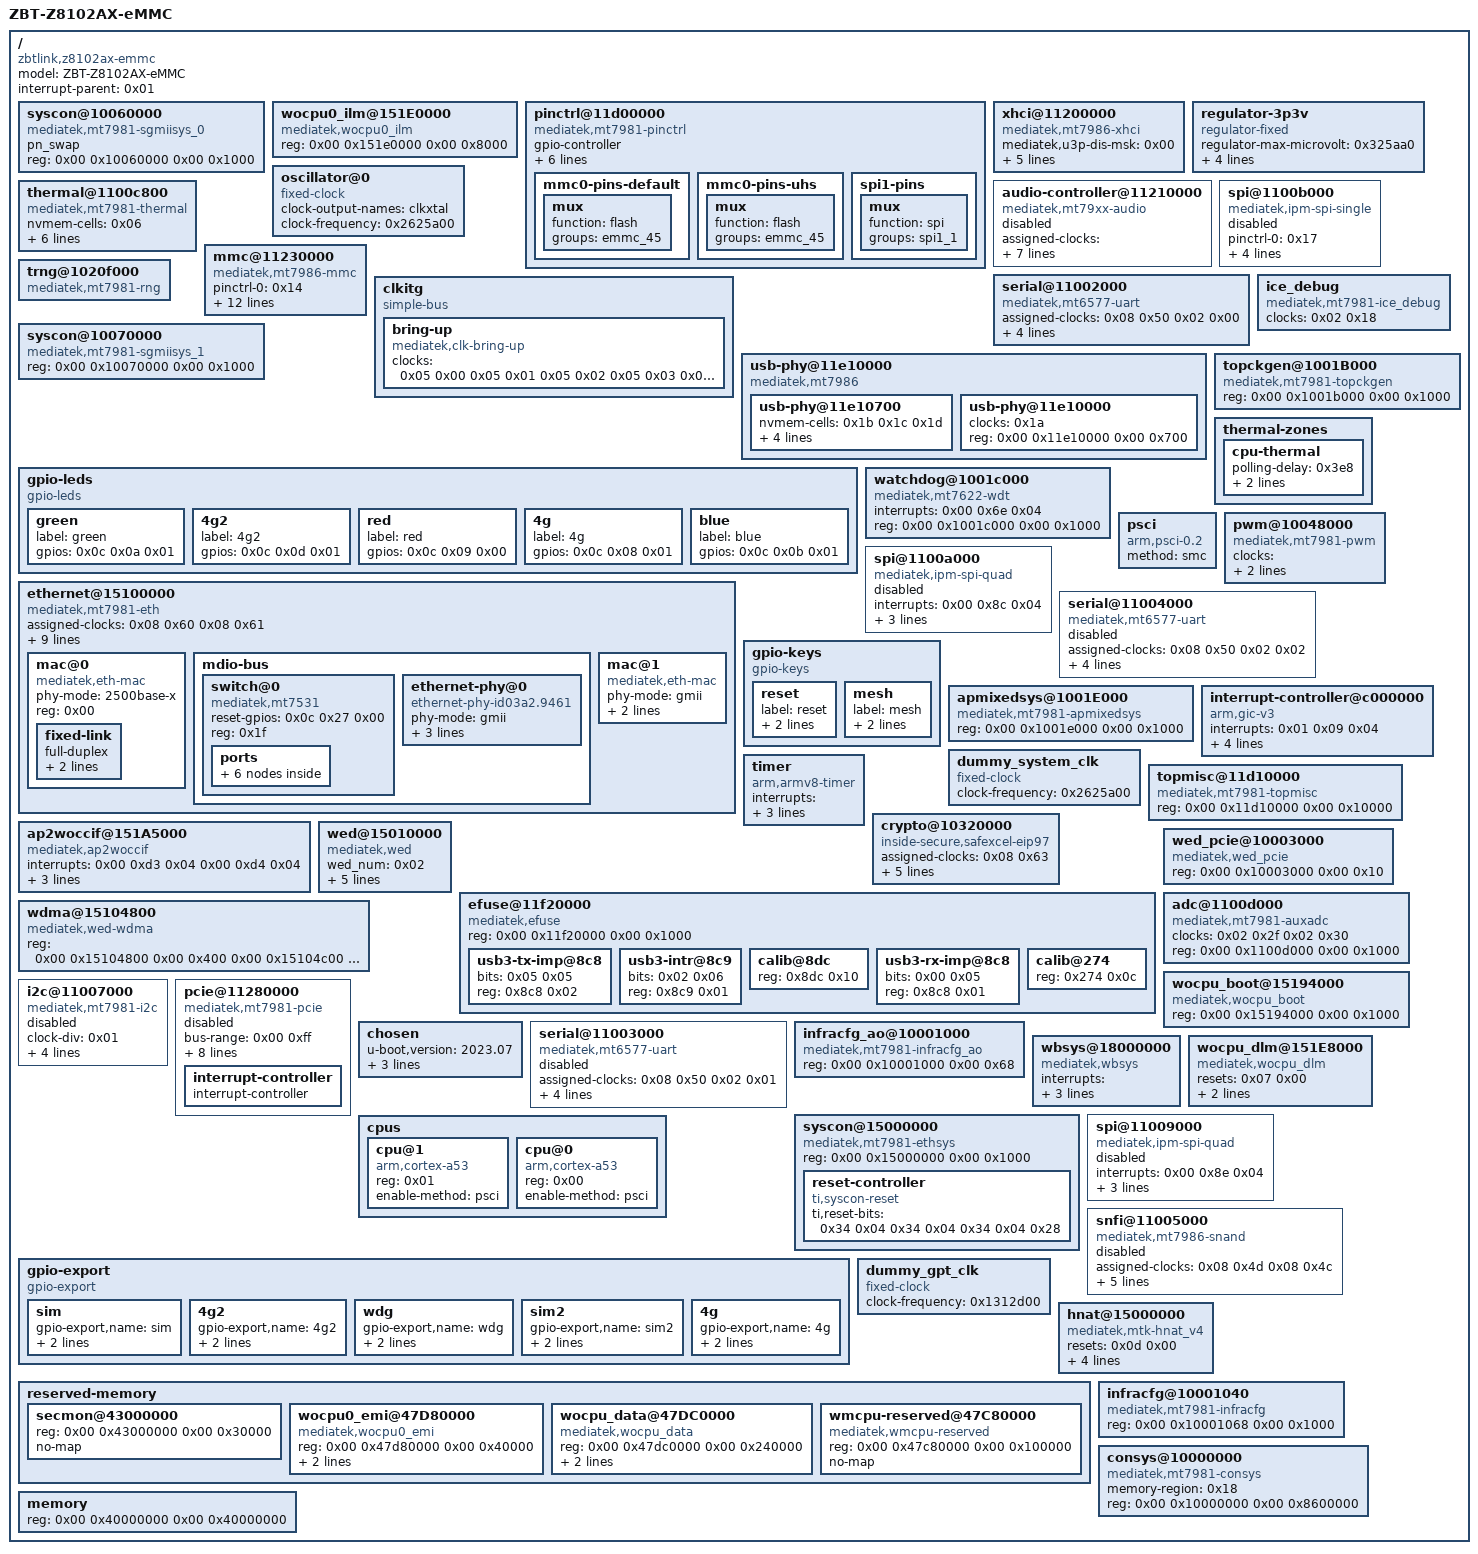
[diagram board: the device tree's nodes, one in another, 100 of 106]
/dts-v1/;

/ {
	#address-cells = <0x02>;
	model = "ZBT-Z8102AX-eMMC";
	#size-cells = <0x02>;
	interrupt-parent = <0x01>;
	compatible = "zbtlink,z8102ax-emmc\0mediatek,mt7981-emmc-rfb";

	syscon@10060000 {
		pn_swap;
		#clock-cells = <0x01>;
		compatible = "mediatek,mt7981-sgmiisys_0\0syscon";
		reg = <0x00 0x10060000 0x00 0x1000>;
		phandle = <0x0e>;
	};

	wocpu0_ilm@151E0000 {
		compatible = "mediatek,wocpu0_ilm";
		reg = <0x00 0x151e0000 0x00 0x8000>;
	};

	pinctrl@11d00000 {
		reg-names = "gpio_base\0iocfg_rt_base\0iocfg_rm_base\0iocfg_rb_base\0iocfg_lb_base\0iocfg_bl_base\0iocfg_tm_base\0iocfg_tl_base\0eint";
		gpio-controller;
		interrupts = <0x00 0xe1 0x04>;
		interrupt-parent = <0x01>;
		compatible = "mediatek,mt7981-pinctrl";
		#interrupt-cells = <0x02>;
		reg = <0x00 0x11d00000 0x00 0x1000 0x00 0x11c00000 0x00 0x1000 0x00 0x11c10000 0x00 0x1000 0x00 0x11d20000 0x00 0x1000 0x00 0x11e00000 0x00 0x1000 0x00 0x11e20000 0x00 0x1000 0x00 0x11f00000 0x00 0x1000 0x00 0x11f10000 0x00 0x1000 0x00 0x1000b000 0x00 0x1000>;
		phandle = <0x0c>;
		#gpio-cells = <0x02>;
		gpio-ranges = <0x0c 0x00 0x00 0x38>;
		interrupt-controller;

		mmc0-pins-default {
			phandle = <0x14>;

			mux {
				function = "flash";
				groups = "emmc_45";
			};
		};

		mmc0-pins-uhs {
			phandle = <0x15>;

			mux {
				function = "flash";
				groups = "emmc_45";
			};
		};

		spi1-pins {
			phandle = <0x17>;

			mux {
				function = "spi";
				groups = "spi1_1";
			};
		};
	};

	xhci@11200000 {
		#address-cells = <0x02>;
		mediatek,u3p-dis-msk = <0x00>;
		clock-names = "sys_ck\0xhci_ck\0ref_ck\0mcu_ck\0dma_ck";
		reg-names = "mac\0ippc";
		interrupts = <0x00 0xad 0x04>;
		clocks = <0x1a 0x1a 0x1a 0x1a 0x1a>;
		#size-cells = <0x02>;
		compatible = "mediatek,mt7986-xhci\0mediatek,mtk-xhci";
		status = "okay";
		phys = <0x19 0x03 0x0a 0x04>;
		reg = <0x00 0x11200000 0x00 0x2e00 0x00 0x11203e00 0x00 0x100>;
	};

	regulator-3p3v {
		regulator-max-microvolt = <0x325aa0>;
		regulator-boot-on;
		regulator-always-on;
		regulator-min-microvolt = <0x325aa0>;
		regulator-name = "fixed-3.3V";
		compatible = "regulator-fixed";
		phandle = <0x16>;
	};

	oscillator@0 {
		clock-output-names = "clkxtal";
		#clock-cells = <0x00>;
		clock-frequency = <0x2625a00>;
		compatible = "fixed-clock";
		phandle = <0x1e>;
	};

	thermal@1100c800 {
		nvmem-cells = <0x06>;
		clock-names = "therm\0auxadc\0adc_32k";
		interrupts = <0x00 0x8a 0x04>;
		clocks = <0x02 0x1c 0x02 0x2f 0x02 0x30>;
		mediatek,apmixedsys = <0x05>;
		#thermal-sensor-cells = <0x01>;
		compatible = "mediatek,mt7981-thermal";
		nvmem-cell-names = "calibration-data";
		reg = <0x00 0x1100c800 0x00 0x800>;
		phandle = <0x03>;
		mediatek,auxadc = <0x04>;
	};

	audio-controller@11210000 {
		clock-names = "aud_bus_ck\0aud_26m_ck\0aud_l_ck\0aud_aud_ck\0aud_eg2_ck\0aud_sel";
		assigned-clocks = <0x08 0x65 0x08 0x66 0x08 0x67 0x08 0x68>;
		assigned-clock-parents = <0x08 0x10 0x08 0x12 0x08 0x10 0x08 0x12>;
		interrupts = <0x00 0x6a 0x04>;
		clocks = <0x02 0x12 0x02 0x13 0x02 0x14 0x02 0x15 0x02 0x16 0x08 0x65>;
		compatible = "mediatek,mt79xx-audio";
		status = "disabled";
		reg = <0x00 0x11210000 0x00 0x9000>;
	};

	spi@1100b000 {
		pinctrl-names = "default";
		pinctrl-0 = <0x17>;
		clock-names = "parent-clk\0sel-clk\0spi-clk\0spi-hclk";
		interrupts = <0x00 0x8d 0x04>;
		clocks = <0x08 0x02 0x08 0x4f 0x02 0x27 0x02 0x29>;
		compatible = "mediatek,ipm-spi-single";
		status = "disabled";
		reg = <0x00 0x1100b000 0x00 0x100>;
	};

	mmc@11230000 {
		pinctrl-names = "default\0state_uhs";
		pinctrl-0 = <0x14>;
		clock-names = "source\0hclk\0source_cg";
		assigned-clocks = <0x08 0x54 0x08 0x55>;
		assigned-clock-parents = <0x08 0x02 0x08 0x1c>;
		bus-width = <0x08>;
		non-removable;
		interrupts = <0x00 0x8f 0x04>;
		clocks = <0x08 0x33 0x08 0x34 0x02 0x2b>;
		vmmc-supply = <0x16>;
		compatible = "mediatek,mt7986-mmc\0mediatek,mt7981-mmc";
		pinctrl-1 = <0x15>;
		status = "okay";
		reg = <0x00 0x11230000 0x00 0x1000 0x00 0x11c20000 0x00 0x1000>;
		max-frequency = <0x3197500>;
		cap-mmc-highspeed;
	};

	serial@11002000 {
		assigned-clocks = <0x08 0x50 0x02 0x00>;
		assigned-clock-parents = <0x08 0x00 0x09 0x01>;
		interrupts = <0x00 0x7b 0x04>;
		clocks = <0x02 0x1e>;
		compatible = "mediatek,mt6577-uart";
		status = "okay";
		reg = <0x00 0x11002000 0x00 0x400>;
	};

	ice_debug {
		clock-names = "ice_dbg";
		clocks = <0x02 0x18>;
		compatible = "mediatek,mt7981-ice_debug\0mediatek,mt2701-ice_debug";
	};

	trng@1020f000 {
		compatible = "mediatek,mt7981-rng";
	};

	clkitg {
		compatible = "simple-bus";

		bring-up {
			clock-names = "0\01\02\03\04\05\06\07\08\09\010\011\012\013\014\015\016\017\018\019\020\021\022\023\024\025\026\027\028\029\030\031\032\033\034\035\036\037\038\039\040\041\042\043\044\045\046\047\048\049\050\051\052\053\054\055\056\057\058\059\060\061\062\063\064\065\066\067\068\069\070\071\072\073\074\075\076\077\078\079\080\081\082\083\084\085\086\087\088\089\090\091\092\093\094\095\096\097\098\099\0100\0101\0102\0103\0104\0105\0106\0107\0108\0109\0110\0111\0112\0113\0114\0115\0116\0117\0118\0119\0120\0121\0122\0123\0124\0125\0126\0127\0128\0129\0130\0131\0132\0133\0134\0135\0136\0137\0138\0139\0140\0141\0142\0143\0144\0145\0146\0147\0148\0149\0150\0151\0152\0153\0154\0155\0156\0157\0158\0159\0160\0161\0162\0163\0164\0165\0166\0167\0168\0169\0170\0171\0172\0173\0174\0175\0176\0177\0178\0179\0180\0181\0182\0183";
			clocks = <0x05 0x00 0x05 0x01 0x05 0x02 0x05 0x03 0x05 0x04 0x05 0x05 0x05 0x06 0x05 0x07 0x09 0x00 0x1e 0x09 0x02 0x09 0x03 0x09 0x04 0x1e 0x09 0x06 0x09 0x07 0x1e 0x1e 0x1e 0x1e 0x09 0x0c 0x09 0x0d 0x09 0x0e 0x09 0x0f 0x09 0x10 0x09 0x11 0x1e 0x1e 0x1e 0x1e 0x1e 0x09 0x17 0x09 0x18 0x09 0x1a 0x09 0x1b 0x09 0x1c 0x09 0x1d 0x09 0x1e 0x09 0x1f 0x09 0x20 0x09 0x21 0x1e 0x09 0x23 0x1e 0x1e 0x1e 0x1e 0x1e 0x1e 0x1e 0x1e 0x1e 0x02 0x0b 0x1e 0x1e 0x1e 0x1e 0x02 0x11 0x1e 0x1e 0x1e 0x1e 0x1e 0x02 0x17 0x1e 0x02 0x19 0x02 0x1a 0x02 0x1b 0x1e 0x1e 0x1e 0x1e 0x1e 0x1e 0x1e 0x1e 0x1e 0x1e 0x1e 0x1e 0x1e 0x1e 0x02 0x2a 0x02 0x2b 0x02 0x2c 0x02 0x2d 0x02 0x2e 0x1e 0x1e 0x02 0x31 0x02 0x32 0x02 0x33 0x02 0x34 0x02 0x35 0x02 0x36 0x02 0x37 0x1e 0x1e 0x1e 0x08 0x01 0x1e 0x08 0x05 0x08 0x06 0x08 0x07 0x08 0x04 0x08 0x09 0x08 0x0c 0x08 0x0f 0x08 0x10 0x08 0x12 0x08 0x14 0x08 0x15 0x08 0x16 0x08 0x17 0x08 0x19 0x08 0x1a 0x1e 0x08 0x1d 0x08 0x1e 0x08 0x21 0x1e 0x08 0x24 0x08 0x25 0x1e 0x08 0x29 0x08 0x26 0x08 0x2b 0x08 0x2a 0x1e 0x08 0x31 0x1e 0x1e 0x1e 0x08 0x56 0x08 0x37 0x08 0x3d 0x08 0x3e 0x08 0x3f 0x08 0x45 0x08 0x41 0x08 0x46 0x08 0x47 0x08 0x48 0x08 0x49 0x08 0x4a 0x08 0x3a 0x1e 0x1e 0x1e 0x1e 0x08 0x52 0x1e 0x1e 0x1e 0x08 0x56 0x08 0x57 0x08 0x58 0x08 0x59 0x08 0x5a 0x08 0x5b 0x08 0x5c 0x08 0x5d 0x08 0x5e 0x08 0x5f 0x1e 0x1e 0x08 0x62 0x08 0x5e 0x1e 0x08 0x64 0x08 0x56 0x08 0x69 0x08 0x6a 0x08 0x6b 0x08 0x6c>;
			compatible = "mediatek,clk-bring-up";
		};
	};

	syscon@10070000 {
		#clock-cells = <0x01>;
		compatible = "mediatek,mt7981-sgmiisys_1\0syscon";
		reg = <0x00 0x10070000 0x00 0x1000>;
		phandle = <0x0f>;
	};

	usb-phy@11e10000 {
		#address-cells = <0x02>;
		#size-cells = <0x02>;
		compatible = "mediatek,mt7986\0mediatek,generic-tphy-v2";
		ranges;
		status = "okay";

		usb-phy@11e10700 {
			nvmem-cells = <0x1b 0x1c 0x1d>;
			clock-names = "ref";
			clocks = <0x1a>;
			#phy-cells = <0x01>;
			status = "okay";
			nvmem-cell-names = "intr\0rx_imp\0tx_imp";
			reg = <0x00 0x11e10700 0x00 0x900>;
			mediatek,syscon-type = <0x10 0x218 0x00>;
			phandle = <0x0a>;
		};

		usb-phy@11e10000 {
			clock-names = "ref";
			clocks = <0x1a>;
			#phy-cells = <0x01>;
			status = "okay";
			reg = <0x00 0x11e10000 0x00 0x700>;
			phandle = <0x19>;
		};
	};

	topckgen@1001B000 {
		#clock-cells = <0x01>;
		compatible = "mediatek,mt7981-topckgen\0syscon";
		reg = <0x00 0x1001b000 0x00 0x1000>;
		phandle = <0x08>;
	};

	gpio-leds {
		compatible = "gpio-leds";

		green {
			label = "green";
			gpios = <0x0c 0x0a 0x01>;
		};

		4g2 {
			label = "4g2";
			gpios = <0x0c 0x0d 0x01>;
		};

		red {
			label = "red";
			gpios = <0x0c 0x09 0x00>;
		};

		4g {
			label = "4g";
			gpios = <0x0c 0x08 0x01>;
		};

		blue {
			label = "blue";
			gpios = <0x0c 0x0b 0x01>;
		};
	};

	thermal-zones {

		cpu-thermal {
			polling-delay = <0x3e8>;
			polling-delay-passive = <0x3e8>;
			thermal-sensors = <0x03 0x00>;
		};
	};

	watchdog@1001c000 {
		#reset-cells = <0x01>;
		interrupts = <0x00 0x6e 0x04>;
		compatible = "mediatek,mt7622-wdt\0mediatek,mt6589-wdt";
		status = "okay";
		reg = <0x00 0x1001c000 0x00 0x1000>;
	};

	psci {
		method = "smc";
		compatible = "arm,psci-0.2";
	};

	pwm@10048000 {
		clock-names = "top\0main\0pwm1\0pwm2\0pwm3";
		clocks = <0x02 0x0d 0x02 0x0c 0x02 0x0e 0x02 0x0f 0x02 0x10>;
		#pwm-cells = <0x02>;
		compatible = "mediatek,mt7981-pwm";
		reg = <0x00 0x10048000 0x00 0x1000>;
	};

	ethernet@15100000 {
		#reset-cells = <0x01>;
		#address-cells = <0x01>;
		clock-names = "fe\0gp2\0gp1\0wocpu0\0sgmii_tx250m\0sgmii_rx250m\0sgmii_cdr_ref\0sgmii_cdr_fb\0sgmii2_tx250m\0sgmii2_rx250m\0sgmii2_cdr_ref\0sgmii2_cdr_fb";
		assigned-clocks = <0x08 0x60 0x08 0x61>;
		assigned-clock-parents = <0x08 0x1b 0x08 0x22>;
		interrupts = <0x00 0xc4 0x04 0x00 0xc5 0x04 0x00 0xc6 0x04 0x00 0xc7 0x04>;
		clocks = <0x0d 0x00 0x0d 0x01 0x0d 0x02 0x0d 0x03 0x0e 0x00 0x0e 0x01 0x0e 0x02 0x0e 0x03 0x0f 0x00 0x0f 0x01 0x0f 0x02 0x0f 0x03>;
		mediatek,sgmiisys = <0x0e 0x0f>;
		#size-cells = <0x00>;
		mediatek,ethsys = <0x0d>;
		compatible = "mediatek,mt7981-eth";
		status = "okay";
		reg = <0x00 0x15100000 0x00 0x80000>;
		mediatek,infracfg = <0x10>;

		mac@0 {
			phy-mode = "2500base-x";
			compatible = "mediatek,eth-mac";
			reg = <0x00>;
			phandle = <0x13>;

			fixed-link {
				full-duplex;
				speed = <0x9c4>;
				pause;
			};
		};

		mdio-bus {
			#address-cells = <0x01>;
			#size-cells = <0x00>;

			switch@0 {
				reset-gpios = <0x0c 0x27 0x00>;
				compatible = "mediatek,mt7531";
				reg = <0x1f>;

				ports {
					#address-cells = <0x01>;
					#size-cells = <0x00>;

					port@0 {
						label = "lan1";
						reg = <0x00>;
					};

					port@3 {
						label = "lan4";
						reg = <0x03>;
					};

					port@1 {
						label = "lan2";
						reg = <0x01>;
					};

					port@6 {
						phy-mode = "2500base-x";
						label = "cpu";
						reg = <0x06>;
						ethernet = <0x13>;

						fixed-link {
							full-duplex;
							speed = <0x9c4>;
							pause;
						};
					};

					port@2 {
						label = "lan3";
						reg = <0x02>;
					};
				};
			};

			ethernet-phy@0 {
				phy-mode = "gmii";
				nvmem-cells = <0x12>;
				compatible = "ethernet-phy-id03a2.9461";
				nvmem-cell-names = "phy-cal-data";
				reg = <0x00>;
				phandle = <0x11>;
			};
		};

		mac@1 {
			phy-mode = "gmii";
			compatible = "mediatek,eth-mac";
			reg = <0x01>;
			phy-handle = <0x11>;
		};
	};

	spi@1100a000 {
		clock-names = "parent-clk\0sel-clk\0spi-clk\0spi-hclk";
		interrupts = <0x00 0x8c 0x04>;
		clocks = <0x08 0x02 0x08 0x4e 0x02 0x26 0x02 0x28>;
		compatible = "mediatek,ipm-spi-quad";
		status = "disabled";
		reg = <0x00 0x1100a000 0x00 0x100>;
	};

	serial@11004000 {
		assigned-clocks = <0x08 0x50 0x02 0x02>;
		assigned-clock-parents = <0x08 0x00 0x09 0x01>;
		interrupts = <0x00 0x7d 0x04>;
		clocks = <0x02 0x20>;
		compatible = "mediatek,mt6577-uart";
		status = "disabled";
		reg = <0x00 0x11004000 0x00 0x400>;
	};

	gpio-keys {
		compatible = "gpio-keys";

		reset {
			label = "reset";
			linux,code = <0x198>;
			gpios = <0x0c 0x01 0x01>;
		};

		mesh {
			label = "mesh";
			linux,code = <0x100>;
			gpios = <0x0c 0x00 0x00>;
		};
	};

	apmixedsys@1001E000 {
		#clock-cells = <0x01>;
		compatible = "mediatek,mt7981-apmixedsys\0syscon";
		reg = <0x00 0x1001e000 0x00 0x1000>;
		phandle = <0x05>;
	};

	interrupt-controller@c000000 {
		interrupts = <0x01 0x09 0x04>;
		interrupt-parent = <0x01>;
		compatible = "arm,gic-v3";
		#interrupt-cells = <0x03>;
		reg = <0x00 0xc000000 0x00 0x40000 0x00 0xc080000 0x00 0x200000>;
		phandle = <0x01>;
		interrupt-controller;
	};

	dummy_system_clk {
		#clock-cells = <0x00>;
		clock-frequency = <0x2625a00>;
		compatible = "fixed-clock";
		phandle = <0x1a>;
	};

	topmisc@11d10000 {
		#clock-cells = <0x01>;
		compatible = "mediatek,mt7981-topmisc\0syscon";
		reg = <0x00 0x11d10000 0x00 0x10000>;
		phandle = <0x10>;
	};

	timer {
		interrupts = <0x01 0x0d 0x08 0x01 0x0e 0x08 0x01 0x0b 0x08 0x01 0x0a 0x08>;
		interrupt-parent = <0x01>;
		clock-frequency = <0xc65d40>;
		compatible = "arm,armv8-timer";
	};

	ap2woccif@151A5000 {
		interrupts = <0x00 0xd3 0x04 0x00 0xd4 0x04>;
		interrupt-parent = <0x01>;
		compatible = "mediatek,ap2woccif";
		reg = <0x00 0x151a5000 0x00 0x1000 0x00 0x151ad000 0x00 0x1000>;
	};

	crypto@10320000 {
		clock-names = "top_eip97_ck";
		assigned-clocks = <0x08 0x63>;
		assigned-clock-parents = <0x08 0x15>;
		interrupts = <0x00 0x74 0x04 0x00 0x75 0x04 0x00 0x76 0x04 0x00 0x77 0x04>;
		clocks = <0x08 0x42>;
		compatible = "inside-secure,safexcel-eip97";
		interrupt-names = "ring0\0ring1\0ring2\0ring3";
		reg = <0x00 0x10320000 0x00 0x40000>;
	};

	wed@15010000 {
		wed_num = <0x02>;
		interrupts = <0x00 0xcd 0x04 0x00 0xce 0x04>;
		interrupt-parent = <0x01>;
		pci_slot_map = <0x00 0x01>;
		compatible = "mediatek,wed";
		reg = <0x00 0x15010000 0x00 0x1000 0x00 0x15011000 0x00 0x1000>;
	};

	efuse@11f20000 {
		#address-cells = <0x01>;
		#size-cells = <0x01>;
		compatible = "mediatek,efuse";
		reg = <0x00 0x11f20000 0x00 0x1000>;

		usb3-tx-imp@8c8 {
			bits = <0x05 0x05>;
			reg = <0x8c8 0x02>;
			phandle = <0x1d>;
		};

		usb3-intr@8c9 {
			bits = <0x02 0x06>;
			reg = <0x8c9 0x01>;
			phandle = <0x1b>;
		};

		calib@8dc {
			reg = <0x8dc 0x10>;
			phandle = <0x12>;
		};

		usb3-rx-imp@8c8 {
			bits = <0x00 0x05>;
			reg = <0x8c8 0x01>;
			phandle = <0x1c>;
		};

		calib@274 {
			reg = <0x274 0x0c>;
			phandle = <0x06>;
		};
	};

	wdma@15104800 {
		compatible = "mediatek,wed-wdma";
		reg = <0x00 0x15104800 0x00 0x400 0x00 0x15104c00 0x00 0x400>;
	};

	wed_pcie@10003000 {
		compatible = "mediatek,wed_pcie";
		reg = <0x00 0x10003000 0x00 0x10>;
	};

	adc@1100d000 {
		clock-names = "main\032k";
		clocks = <0x02 0x2f 0x02 0x30>;
		#io-channel-cells = <0x01>;
		compatible = "mediatek,mt7981-auxadc\0mediatek,mt7622-auxadc";
		reg = <0x00 0x1100d000 0x00 0x1000>;
		phandle = <0x04>;
	};

	wocpu_boot@15194000 {
		compatible = "mediatek,wocpu_boot";
		reg = <0x00 0x15194000 0x00 0x1000>;
	};

	i2c@11007000 {
		clock-div = <0x01>;
		#address-cells = <0x01>;
		clock-names = "main\0dma";
		interrupts = <0x00 0x88 0x04>;
		clocks = <0x02 0x1d 0x02 0x19>;
		#size-cells = <0x00>;
		compatible = "mediatek,mt7981-i2c";
		status = "disabled";
		reg = <0x00 0x11007000 0x00 0x1000 0x00 0x10217080 0x00 0x80>;
	};

	pcie@11280000 {
		#address-cells = <0x03>;
		phy-names = "pcie-phy";
		bus-range = <0x00 0xff>;
		reg-names = "pcie-mac";
		interrupts = <0x00 0xa8 0x04>;
		clocks = <0x02 0x38 0x02 0x39 0x02 0x3a 0x02 0x3b>;
		interrupt-map = <0x00 0x00 0x00 0x01 0x0b 0x00 0x00 0x00 0x00 0x02 0x0b 0x01 0x00 0x00 0x00 0x03 0x0b 0x02 0x00 0x00 0x00 0x04 0x0b 0x03>;
		#size-cells = <0x02>;
		device_type = "pci";
		interrupt-map-mask = <0x00 0x00 0x00 0x07>;
		compatible = "mediatek,mt7981-pcie\0mediatek,mt7986-pcie";
		ranges = <0x82000000 0x00 0x20000000 0x00 0x20000000 0x00 0x10000000>;
		#interrupt-cells = <0x01>;
		status = "disabled";
		phys = <0x0a 0x02>;
		reg = <0x00 0x11280000 0x00 0x4000>;

		interrupt-controller {
			#address-cells = <0x00>;
			#interrupt-cells = <0x01>;
			phandle = <0x0b>;
			interrupt-controller;
		};
	};

	chosen {
		u-boot,version = "2023.07";
		bootargs = "earlycon=uart8250,mmio32,0x11002000 console=ttyS0,115200n8 root=/dev/mmcblk0p6";
		u-boot,bootconf = "config-1";
	};

	serial@11003000 {
		assigned-clocks = <0x08 0x50 0x02 0x01>;
		assigned-clock-parents = <0x08 0x00 0x09 0x01>;
		interrupts = <0x00 0x7c 0x04>;
		clocks = <0x02 0x1f>;
		compatible = "mediatek,mt6577-uart";
		status = "disabled";
		reg = <0x00 0x11003000 0x00 0x400>;
	};

	infracfg_ao@10001000 {
		#clock-cells = <0x01>;
		compatible = "mediatek,mt7981-infracfg_ao\0syscon";
		reg = <0x00 0x10001000 0x00 0x68>;
		phandle = <0x02>;
	};

	wbsys@18000000 {
		interrupts = <0x00 0xd5 0x04 0x00 0xd6 0x04 0x00 0xd7 0x04 0x00 0xd8 0x04>;
		compatible = "mediatek,wbsys";
		chip_id = <0x7981>;
		reg = <0x00 0x18000000 0x00 0x1000000>;
	};

	wocpu_dlm@151E8000 {
		resets = <0x07 0x00>;
		compatible = "mediatek,wocpu_dlm";
		reg = <0x00 0x151e8000 0x00 0x2000 0x00 0x151f8000 0x00 0x2000>;
		reset-names = "wocpu_rst";
	};

	syscon@15000000 {
		#reset-cells = <0x01>;
		#address-cells = <0x01>;
		#size-cells = <0x01>;
		#clock-cells = <0x01>;
		compatible = "mediatek,mt7981-ethsys\0syscon";
		reg = <0x00 0x15000000 0x00 0x1000>;
		phandle = <0x0d>;

		reset-controller {
			#reset-cells = <0x01>;
			ti,reset-bits = <0x34 0x04 0x34 0x04 0x34 0x04 0x28>;
			compatible = "ti,syscon-reset";
			phandle = <0x07>;
		};
	};

	spi@11009000 {
		clock-names = "parent-clk\0sel-clk\0spi-clk\0spi-hclk";
		interrupts = <0x00 0x8e 0x04>;
		clocks = <0x08 0x02 0x08 0x4e 0x02 0x21 0x02 0x22>;
		compatible = "mediatek,ipm-spi-quad";
		status = "disabled";
		reg = <0x00 0x11009000 0x00 0x100>;
	};

	cpus {
		#address-cells = <0x01>;
		#size-cells = <0x00>;

		cpu@1 {
			device_type = "cpu";
			compatible = "arm,cortex-a53";
			reg = <0x01>;
			enable-method = "psci";
		};

		cpu@0 {
			device_type = "cpu";
			compatible = "arm,cortex-a53";
			reg = <0x00>;
			enable-method = "psci";
		};
	};

	gpio-export {
		#size-cells = <0x00>;
		compatible = "gpio-export";

		sim {
			gpio-export,name = "sim";
			gpio-export,output = <0x01>;
			gpios = <0x0c 0x06 0x00>;
		};

		4g2 {
			gpio-export,name = "4g2";
			gpio-export,output = <0x01>;
			gpios = <0x0c 0x05 0x00>;
		};

		wdg {
			gpio-export,name = "wdg";
			gpio-export,output = <0x01>;
			gpios = <0x0c 0x02 0x00>;
		};

		sim2 {
			gpio-export,name = "sim2";
			gpio-export,output = <0x01>;
			gpios = <0x0c 0x07 0x00>;
		};

		4g {
			gpio-export,name = "4g";
			gpio-export,output = <0x01>;
			gpios = <0x0c 0x04 0x00>;
		};
	};

	snfi@11005000 {
		#address-cells = <0x01>;
		clock-names = "pad_clk\0nfi_clk\0nfi_hclk";
		reg-names = "nfi\0ecc";
		assigned-clocks = <0x08 0x4d 0x08 0x4c>;
		assigned-clock-parents = <0x08 0x06 0x08 0x06>;
		interrupts = <0x00 0x79 0x04>;
		clocks = <0x02 0x24 0x02 0x23 0x02 0x25>;
		#size-cells = <0x00>;
		compatible = "mediatek,mt7986-snand";
		status = "disabled";
		reg = <0x00 0x11005000 0x00 0x1000 0x00 0x11006000 0x00 0x1000>;
	};

	dummy_gpt_clk {
		#clock-cells = <0x00>;
		clock-frequency = <0x1312d00>;
		compatible = "fixed-clock";
	};

	hnat@15000000 {
		resets = <0x0d 0x00>;
		mtketh-wan = "eth1";
		compatible = "mediatek,mtk-hnat_v4";
		status = "okay";
		reg = <0x00 0x15100000 0x00 0x80000>;
		reset-names = "mtketh";
		mtketh-max-gmac = <0x02>;
		mtketh-lan = "lan";
	};

	reserved-memory {
		#address-cells = <0x02>;
		#size-cells = <0x02>;
		ranges;

		secmon@43000000 {
			reg = <0x00 0x43000000 0x00 0x30000>;
			no-map;
		};

		wocpu0_emi@47D80000 {
			compatible = "mediatek,wocpu0_emi";
			reg = <0x00 0x47d80000 0x00 0x40000>;
			no-map;
			shared = <0x00>;
		};

		wocpu_data@47DC0000 {
			compatible = "mediatek,wocpu_data";
			reg = <0x00 0x47dc0000 0x00 0x240000>;
			no-map;
			shared = <0x01>;
		};

		wmcpu-reserved@47C80000 {
			compatible = "mediatek,wmcpu-reserved";
			reg = <0x00 0x47c80000 0x00 0x100000>;
			phandle = <0x18>;
			no-map;
		};
	};

	infracfg@10001040 {
		#clock-cells = <0x01>;
		compatible = "mediatek,mt7981-infracfg\0syscon";
		reg = <0x00 0x10001068 0x00 0x1000>;
		phandle = <0x09>;
	};

	consys@10000000 {
		memory-region = <0x18>;
		compatible = "mediatek,mt7981-consys";
		reg = <0x00 0x10000000 0x00 0x8600000>;
	};

	memory {
		device_type = "memory";
		reg = <0x00 0x40000000 0x00 0x40000000>;
	};
};
